# ESP32C5_RADIO register map
Vendor: Espressif; Series: ESP32-C5; File version: 0.1
Registers are 32-bit, read-write, no defined reset value unless marked. A register's access mark holds for its fields unless they carry their own. Offsets are from the block's base; [hi:lo] are bit positions; lines under a group give offsets from that group; {n}, {i} and the like mark numbered series.

## PCR_TIMG1 — Peripheral clock/reset registers: timer group 1's bus clock, reset and watchdog clock words.
Base 0x60096000
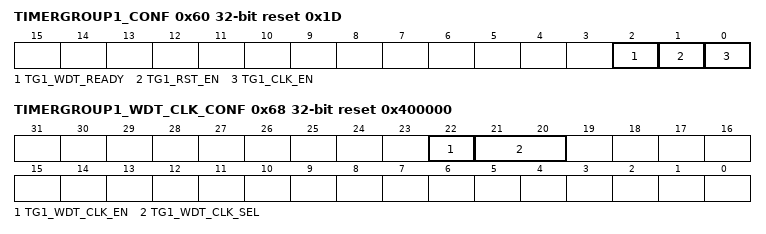
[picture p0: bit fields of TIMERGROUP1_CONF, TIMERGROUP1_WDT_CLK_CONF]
0x60 TIMERGROUP1_CONF reset 0x1D — Timer group 1 bus clock and reset.
  [2] TG1_WDT_READY ro — The watchdog is out of reset and ready.
  [1] TG1_RST_EN — Holds timer group 1 in reset while set.
  [0] TG1_CLK_EN — Timer group 1 bus clock enable.
0x68 TIMERGROUP1_WDT_CLK_CONF reset 0x400000 — Timer group 1 watchdog clock source and enable.
  [22] TG1_WDT_CLK_EN — Watchdog clock enable.
  [21:20] TG1_WDT_CLK_SEL — Watchdog clock source: 0 XTAL, 1 PLL_F80M, 2 RC_FAST.

## PCR_UART0_CLOCK — Peripheral clock/reset registers: UART0's function clock, which the boot ROM prints through after a software reset.
Base 0x60096000
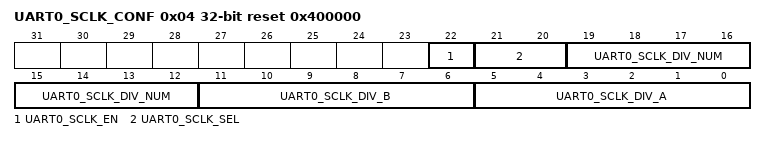
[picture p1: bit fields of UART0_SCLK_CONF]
0x04 UART0_SCLK_CONF reset 0x400000 — UART0's function clock: divider, source and enable.
  [22] UART0_SCLK_EN — Function clock enable.
  [21:20] UART0_SCLK_SEL — Function clock source: 0 XTAL, 1 RC_FAST, 2 PLL_F80M.
  [19:12] UART0_SCLK_DIV_NUM — Integral part of the function clock divider; zero divides by one.
  [11:6] UART0_SCLK_DIV_B — Numerator of the function clock divider's fractional part.
  [5:0] UART0_SCLK_DIV_A — Denominator of the function clock divider's fractional part.

## SYSTIMER — The system timer's comparators: their enables in CONF, targets, modes, load strobes and interrupt enables; their acknowledgements are SYSTIMER_ACKNOWLEDGE. The counter latch of unit zero is the separate shared block SYSTIMER_COUNTER; unit one, the unit loads and the read-back registers are not described.
Base 0x6000A000
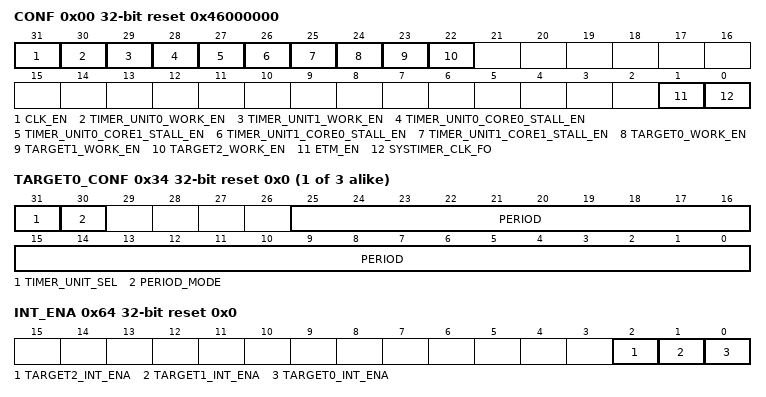
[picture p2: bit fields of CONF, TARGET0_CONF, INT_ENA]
0x00 CONF reset 0x46000000 — Project-assigned name. Clock, unit and comparator enables.
  [31] CLK_EN — Project-assigned name. Keeps the register clock enabled for every access.
  [30] TIMER_UNIT0_WORK_EN — Project-assigned name. Enables unit 0.
  [29] TIMER_UNIT1_WORK_EN — Project-assigned name. Enables unit 1.
  [28] TIMER_UNIT0_CORE0_STALL_EN — Project-assigned name. Stalls unit 0 while core 0 is stalled.
  [27] TIMER_UNIT0_CORE1_STALL_EN — Project-assigned name. Stalls unit 0 while core 1 is stalled.
  [26] TIMER_UNIT1_CORE0_STALL_EN — Project-assigned name. Stalls unit 1 while core 0 is stalled.
  [25] TIMER_UNIT1_CORE1_STALL_EN — Project-assigned name. Stalls unit 1 while core 1 is stalled.
  [24] TARGET0_WORK_EN — Project-assigned name. Enables comparator 0.
  [23] TARGET1_WORK_EN — Project-assigned name. Enables comparator 1.
  [22] TARGET2_WORK_EN — Project-assigned name. Enables comparator 2.
  [1] ETM_EN — Project-assigned name. Enables the generation of ETM events.
  [0] SYSTIMER_CLK_FO — Project-assigned name. Forces the system timer clock on.
{0x1C+8i} TARGET{i}_HI (i=0..2) reset 0x0 — Project-assigned name. High 20 bits of comparator {i}'s alarm target.
  [19:0] HI — Project-assigned name. Target bits 51:32.
{0x20+8i} TARGET{i}_LO (i=0..2) reset 0x0 — Project-assigned name. Low 32 bits of comparator {i}'s alarm target.
  [31:0] LO — Project-assigned name. Target bits 31:0.
{0x34+4i} TARGET{i}_CONF (i=0..2) reset 0x0 — Project-assigned name. Alarm mode of comparator {i}.
  [31] TIMER_UNIT_SEL — Project-assigned name. Selects unit 1 instead of unit 0 as the compared counter.
  [30] PERIOD_MODE — Project-assigned name. Selects period mode instead of one-shot target mode.
  [25:0] PERIOD — Project-assigned name. Alarm period in period mode.
{0x50+4i} COMP{i}_LOAD (i=0..2) wo reset 0x0 — Project-assigned name. Load strobe of comparator {i}: writing one loads its target and mode.
  [0] LOAD — Project-assigned name. Loads the comparator's target and mode.
0x64 INT_ENA reset 0x0 — Project-assigned name. Comparator interrupt enables.
  [2] TARGET2_INT_ENA — Project-assigned name. Enables comparator 2's interrupt.
  [1] TARGET1_INT_ENA — Project-assigned name. Enables comparator 1's interrupt.
  [0] TARGET0_INT_ENA — Project-assigned name. Enables comparator 0's interrupt.
